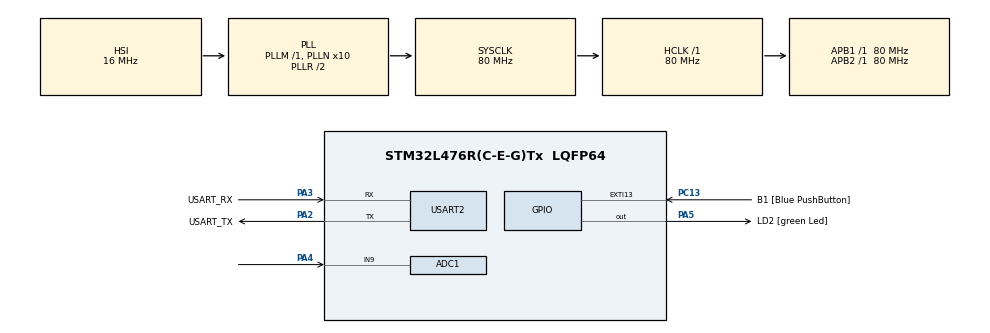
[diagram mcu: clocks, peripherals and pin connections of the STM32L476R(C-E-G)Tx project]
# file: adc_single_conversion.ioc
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ADC1.Channel-1\#ChannelRegularConversion=ADC_CHANNEL_9
ADC1.DataAlign=ADC_DATAALIGN_RIGHT
ADC1.NbrOfConversionFlag=1
ADC1.OffsetNumber-1\#ChannelRegularConversion=ADC_OFFSET_NONE
ADC1.Rank-1\#ChannelRegularConversion=1
ADC1.SamplingTime-1\#ChannelRegularConversion=ADC_SAMPLETIME_2CYCLES_5
ADC1.master=1
Mcu.Family=STM32L4
Mcu.Name=STM32L476R(C-E-G)Tx
Mcu.Package=LQFP64
NVIC.EXTI15_10_IRQn=true\:0\:0\:false\:false\:true\:true\:true\:true
NVIC.PriorityGroup=NVIC_PRIORITYGROUP_4
PA13\ (JTMS-SWDIO).GPIO_Label=TMS
PA13\ (JTMS-SWDIO).Mode=Serial_Wire
PA13\ (JTMS-SWDIO).Signal=SYS_JTMS-SWDIO
PA14\ (JTCK-SWCLK).GPIO_Label=TCK
PA14\ (JTCK-SWCLK).Mode=Serial_Wire
PA14\ (JTCK-SWCLK).Signal=SYS_JTCK-SWCLK
PA2.GPIO_Label=USART_TX
PA2.GPIO_Mode=GPIO_MODE_AF_PP
PA2.GPIO_PuPd=GPIO_NOPULL
PA2.GPIO_Speed=GPIO_SPEED_FREQ_VERY_HIGH
PA2.Mode=Asynchronous
PA2.Signal=USART2_TX
PA3.GPIO_Label=USART_RX
PA3.GPIO_Mode=GPIO_MODE_AF_PP
PA3.GPIO_PuPd=GPIO_NOPULL
PA3.GPIO_Speed=GPIO_SPEED_FREQ_VERY_HIGH
PA3.Mode=Asynchronous
PA3.Signal=USART2_RX
PA4.Signal=ADCx_IN9
PA5.GPIO_Label=LD2 [green Led]
PA5.GPIO_ModeDefaultOutputPP=GPIO_MODE_OUTPUT_PP
PA5.GPIO_PuPd=GPIO_NOPULL
PA5.GPIO_Speed=GPIO_SPEED_FREQ_LOW
PA5.Signal=GPIO_Output
PB3\ (JTDO-TRACESWO).GPIO_Label=SWO
PB3\ (JTDO-TRACESWO).Signal=SYS_JTDO-SWO
PC13.GPIO_Label=B1 [Blue PushButton]
PC13.GPIO_ModeDefaultEXTI=GPIO_MODE_IT_FALLING
PC13.GPIO_PuPd=GPIO_NOPULL
PC13.Signal=GPXTI13
PC14-OSC32_IN\ (PC14).Mode=LSE-External-Oscillator
PC14-OSC32_IN\ (PC14).Signal=RCC_OSC32_IN
PC15-OSC32_OUT\ (PC15).Mode=LSE-External-Oscillator
PC15-OSC32_OUT\ (PC15).Signal=RCC_OSC32_OUT
PH0-OSC_IN\ (PH0).Signal=RCC_OSC_IN
PH1-OSC_OUT\ (PH1).Signal=RCC_OSC_OUT
ProjectManager.HeapSize=0x200
ProjectManager.StackSize=0x400
ProjectManager.TargetToolchain=STM32CubeIDE
RCC.ADCFreq_Value=64000000
RCC.AHBFreq_Value=80000000
RCC.APB1Freq_Value=80000000
RCC.APB1TimFreq_Value=80000000
RCC.APB2Freq_Value=80000000
RCC.APB2TimFreq_Value=80000000
RCC.CortexFreq_Value=80000000
RCC.HCLKFreq_Value=80000000
RCC.HSE_VALUE=8000000
RCC.HSI_VALUE=16000000
RCC.MSI_VALUE=4000000
RCC.PLLN=10
RCC.PLLSourceVirtual=RCC_PLLSOURCE_HSI
RCC.PREFETCH_ENABLE=1
RCC.SYSCLKFreq_VALUE=80000000
RCC.SYSCLKSource=RCC_SYSCLKSOURCE_PLLCLK
RCC.USBFreq_Value=64000000
RCC.VCOOutputFreq_Value=160000000
SH.ADCx_IN9.0=ADC1_IN9,IN9-Single-Ended
USART2.VirtualMode-Asynchronous=VM_ASYNC
board=NUCLEO-L476RG

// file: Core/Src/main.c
/* USER CODE BEGIN Header */
/**
  ******************************************************************************
  * @file           : main.c
  * @brief          : Main program body
  ******************************************************************************
  * @attention
  *
  * Copyright (c) 2025 STMicroelectronics.
  * All rights reserved.
  *
  * This software is licensed under terms that can be found in the LICENSE file
  * in the root directory of this software component.
  * If no LICENSE file comes with this software, it is provided AS-IS.
  *
  ******************************************************************************
  */
/* USER CODE END Header */
/* USER CODE BEGIN Header */
/**
  ******************************************************************************
  * @file           : main.c
  * @brief          : Main program body
  ******************************************************************************
  * @attention
  *
  * STM32 ADC example: Reads ADC value on button press (B1), turns on LED if
  * voltage > 1.65V, and prints ADC value via UART.
  *
  ******************************************************************************
  */
/* USER CODE END Header */

#include "main.h"
#include <stdio.h>
#include "string.h"

// Variable to store the ADC reading
uint32_t adc_value = 0;

ADC_HandleTypeDef hadc1;  // ADC1 handle
UART_HandleTypeDef huart2; // UART2 handle

void SystemClock_Config(void);
static void MX_GPIO_Init(void);
static void MX_USART2_UART_Init(void);
static void MX_ADC1_Init(void);

/* USER CODE BEGIN 0 */

// Callback function called when a GPIO interrupt occurs
void HAL_GPIO_EXTI_Callback(uint16_t GPIO_Pin)
{
    // Check if the interrupt is triggered by button B1 (PC13)
    if (GPIO_Pin == B1_Pin)
    {
        HAL_ADC_Start(&hadc1); // Start single ADC conversion

        // Wait for conversion to complete (blocking call)
        if (HAL_ADC_PollForConversion(&hadc1, HAL_MAX_DELAY) == HAL_OK)
        {
            adc_value = HAL_ADC_GetValue(&hadc1); // Read ADC value (12-bit, 0-4095)

            // Example: Toggle LED based on ADC voltage threshold (~1.65V)
            // 12-bit ADC: 4096 -> 3.3V, so 2048 -> 1.65V
            if (adc_value > 2048)
                HAL_GPIO_WritePin(LD2_GPIO_Port, LD2_Pin, GPIO_PIN_SET);   // Turn LED ON
            else
                HAL_GPIO_WritePin(LD2_GPIO_Port, LD2_Pin, GPIO_PIN_RESET); // Turn LED OFF
        }

        HAL_ADC_Stop(&hadc1); // Stop ADC (optional, since single conversion mode)
    }
}

/* USER CODE END 0 */

/**
  * @brief  Main program
  * @retval int
  */
int main(void)
{
    HAL_Init();              // Initialize HAL library
    SystemClock_Config();    // Configure system clock

    // Initialize all peripherals
    MX_GPIO_Init();
    MX_USART2_UART_Init();
    MX_ADC1_Init();

    /* Infinite loop */
    while (1)
    {
        // Transmit ADC value continuously via UART (for monitoring)
        char msg[30];
        snprintf(msg, sizeof(msg), "ADC: %lu\r\n", adc_value); // Format ADC value as string
        HAL_UART_Transmit(&huart2, (uint8_t*)msg, strlen(msg), HAL_MAX_DELAY);

        HAL_Delay(500); // Delay 500ms
    }
}

void SystemClock_Config(void)
{
    RCC_OscInitTypeDef RCC_OscInitStruct = {0};
    RCC_ClkInitTypeDef RCC_ClkInitStruct = {0};

    HAL_PWREx_ControlVoltageScaling(PWR_REGULATOR_VOLTAGE_SCALE1);

    // Configure HSI oscillator and PLL
    RCC_OscInitStruct.OscillatorType = RCC_OSCILLATORTYPE_HSI;
    RCC_OscInitStruct.HSIState = RCC_HSI_ON;
    RCC_OscInitStruct.HSICalibrationValue = RCC_HSICALIBRATION_DEFAULT;
    RCC_OscInitStruct.PLL.PLLState = RCC_PLL_ON;
    RCC_OscInitStruct.PLL.PLLSource = RCC_PLLSOURCE_HSI;
    RCC_OscInitStruct.PLL.PLLM = 1;
    RCC_OscInitStruct.PLL.PLLN = 10;
    RCC_OscInitStruct.PLL.PLLP = RCC_PLLP_DIV7;
    RCC_OscInitStruct.PLL.PLLQ = RCC_PLLQ_DIV2;
    RCC_OscInitStruct.PLL.PLLR = RCC_PLLR_DIV2;
    HAL_RCC_OscConfig(&RCC_OscInitStruct);

    // Configure CPU, AHB, and APB clocks
    RCC_ClkInitStruct.ClockType = RCC_CLOCKTYPE_HCLK|RCC_CLOCKTYPE_SYSCLK
                                |RCC_CLOCKTYPE_PCLK1|RCC_CLOCKTYPE_PCLK2;
    RCC_ClkInitStruct.SYSCLKSource = RCC_SYSCLKSOURCE_PLLCLK;
    RCC_ClkInitStruct.AHBCLKDivider = RCC_SYSCLK_DIV1;
    RCC_ClkInitStruct.APB1CLKDivider = RCC_HCLK_DIV1;
    RCC_ClkInitStruct.APB2CLKDivider = RCC_HCLK_DIV1;
    HAL_RCC_ClockConfig(&RCC_ClkInitStruct, FLASH_LATENCY_4);
}

/**
  * @brief ADC1 Initialization
  */
static void MX_ADC1_Init(void)
{
    ADC_ChannelConfTypeDef sConfig = {0};
    ADC_MultiModeTypeDef multimode = {0};

    hadc1.Instance = ADC1;
    hadc1.Init.ClockPrescaler = ADC_CLOCK_ASYNC_DIV1;
    hadc1.Init.Resolution = ADC_RESOLUTION_12B;     // 12-bit ADC
    hadc1.Init.DataAlign = ADC_DATAALIGN_RIGHT;     // Right-align data
    hadc1.Init.ScanConvMode = ADC_SCAN_DISABLE;     // Single channel
    hadc1.Init.EOCSelection = ADC_EOC_SINGLE_CONV;  // End of conversion flag
    hadc1.Init.ContinuousConvMode = DISABLE;        // Single conversion mode
    hadc1.Init.NbrOfConversion = 1;                 // Only 1 channel
    hadc1.Init.ExternalTrigConv = ADC_SOFTWARE_START;
    hadc1.Init.DMAContinuousRequests = DISABLE;

    HAL_ADC_Init(&hadc1);

    // ADC multi-mode configuration: independent
    multimode.Mode = ADC_MODE_INDEPENDENT;
    HAL_ADCEx_MultiModeConfigChannel(&hadc1, &multimode);

    // Configure regular channel: ADC_CHANNEL_9 (PA4)
    sConfig.Channel = ADC_CHANNEL_9;
    sConfig.Rank = ADC_REGULAR_RANK_1;
    sConfig.SamplingTime = ADC_SAMPLETIME_2CYCLES_5;
    sConfig.SingleDiff = ADC_SINGLE_ENDED;
    HAL_ADC_ConfigChannel(&hadc1, &sConfig);
}

/**
  * @brief USART2 Initialization
  */
static void MX_USART2_UART_Init(void)
{
    huart2.Instance = USART2;
    huart2.Init.BaudRate = 115200; // UART speed
    huart2.Init.WordLength = UART_WORDLENGTH_8B;
    huart2.Init.StopBits = UART_STOPBITS_1;
    huart2.Init.Parity = UART_PARITY_NONE;
    huart2.Init.Mode = UART_MODE_TX_RX;
    huart2.Init.HwFlowCtl = UART_HWCONTROL_NONE;
    huart2.Init.OverSampling = UART_OVERSAMPLING_16;
    HAL_UART_Init(&huart2);
}

/**
  * @brief GPIO Initialization
  */
static void MX_GPIO_Init(void)
{
    GPIO_InitTypeDef GPIO_InitStruct = {0};

    // Enable GPIO clocks
    __HAL_RCC_GPIOC_CLK_ENABLE();
    __HAL_RCC_GPIOH_CLK_ENABLE();
    __HAL_RCC_GPIOA_CLK_ENABLE();
    __HAL_RCC_GPIOB_CLK_ENABLE();

    // Set LD2 (LED) pin low initially
    HAL_GPIO_WritePin(LD2_GPIO_Port, LD2_Pin, GPIO_PIN_RESET);

    // Configure button B1 (PC13) as input with falling edge interrupt
    GPIO_InitStruct.Pin = B1_Pin;
    GPIO_InitStruct.Mode = GPIO_MODE_IT_FALLING;
    GPIO_InitStruct.Pull = GPIO_NOPULL;
    HAL_GPIO_Init(B1_GPIO_Port, &GPIO_InitStruct);

    // Configure LED2 pin as output push-pull
    GPIO_InitStruct.Pin = LD2_Pin;
    GPIO_InitStruct.Mode = GPIO_MODE_OUTPUT_PP;
    GPIO_InitStruct.Pull = GPIO_NOPULL;
    GPIO_InitStruct.Speed = GPIO_SPEED_FREQ_LOW;
    HAL_GPIO_Init(LD2_GPIO_Port, &GPIO_InitStruct);

    // Enable EXTI interrupt for button (PC13)
    HAL_NVIC_SetPriority(EXTI15_10_IRQn, 0, 0);
    HAL_NVIC_EnableIRQ(EXTI15_10_IRQn);
}

void Error_Handler(void)
{
  __disable_irq();
  while (1)
  {
  }
}
